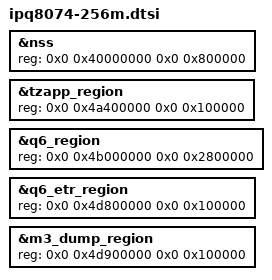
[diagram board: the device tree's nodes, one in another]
// SPDX-License-Identifier: GPL-2.0-only

#include "ipq8074.dtsi"

&nss {
	reg = <0x0 0x40000000 0x0 0x800000>;
};

&tzapp_region {
	reg = <0x0 0x4a400000 0x0 0x100000>;
};

&q6_region {
	reg = <0x0 0x4b000000 0x0 0x2800000>;
};

&q6_etr_region {
	reg = <0x0 0x4d800000 0x0 0x100000>;
};

&m3_dump_region {
	reg = <0x0 0x4d900000 0x0 0x100000>;
};
